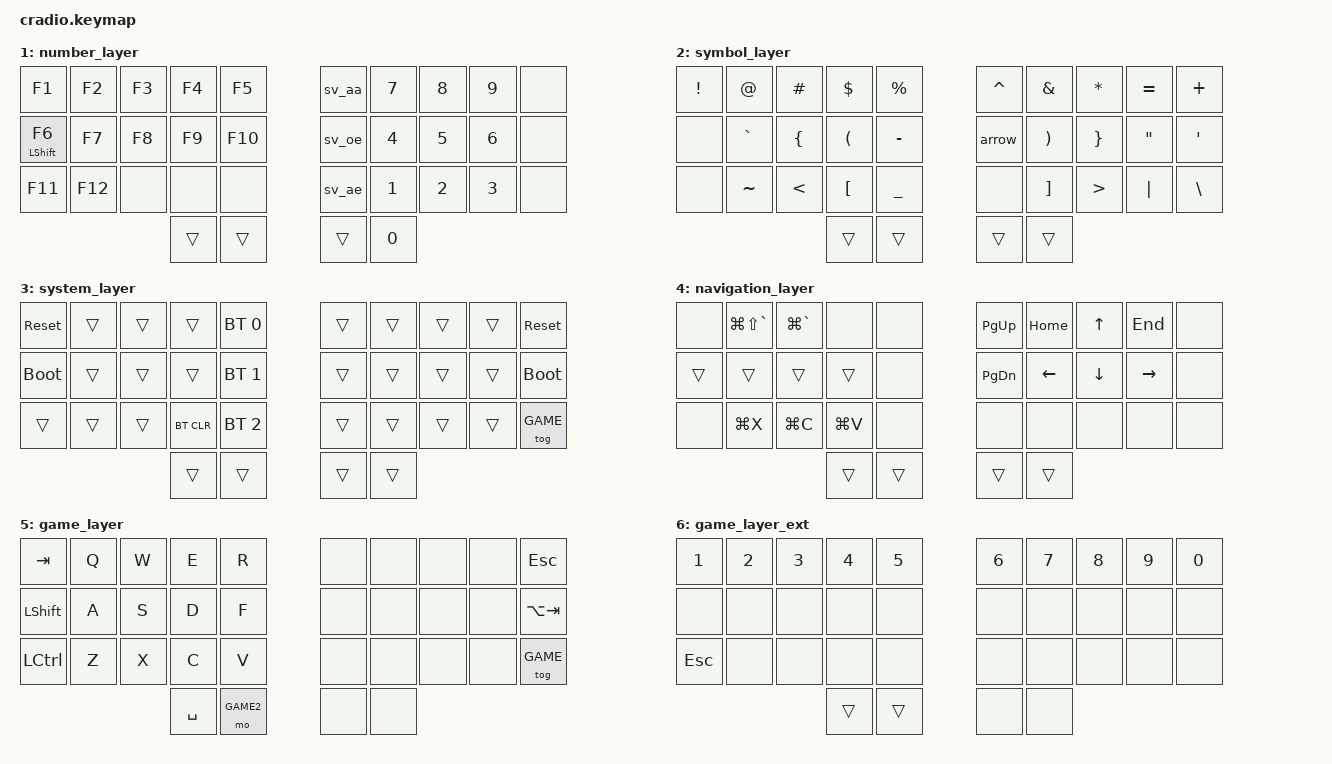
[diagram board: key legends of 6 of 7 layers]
// Copyright (c) 2022 The ZMK Contributors
// SPDX-License-Identifier: MIT

#include <behaviors.dtsi>
#include <dt-bindings/zmk/keys.h>
#include <dt-bindings/zmk/bt.h>

// Layer names
#define DEFAULT 0
#define NUM 1
#define SYM 2
#define SYS 3
#define NAV 4
#define GAME 5
#define GAME2 6

// Home row mods macro
#define HRML(k1,k2,k3,k4) &lhm LSHFT k1  &lhm LCTRL k2  &lhm LALT k3  &lhm LGUI k4
#define HRMR(k1,k2,k3,k4) &rhm RGUI k1  &rhm RALT k2  &rhm RCTRL k3  &rhm RSHFT k4

#define COMBO(NAME, BINDINGS, KEYPOS) \
    combo_##NAME { \
        timeout-ms = <40>; \
        bindings = <BINDINGS>; \
        key-positions = <KEYPOS>; \
	    layers = <DEFAULT NAV>; \
    }

/ {
    behaviors {
        ht: hold_tap {
            label = "hold_tap";
            compatible = "zmk,behavior-hold-tap";
            #binding-cells = <2>;
            flavor = "tap-preferred";
            tapping-term-ms = <250>;
            quick-tap-ms = <150>;
            //global-quick-tap;
            retro-tap;
            bindings = <&kp>, <&kp>;
        };

        lhm: left_homerow_mods {
            compatible = "zmk,behavior-hold-tap";
            label = "LEFT_HOMEROW_MODS";
            #binding-cells = <2>;
            flavor = "balanced";
            tapping-term-ms = <250>;
            //quick-tap-ms = <150>;
            hold-trigger-on-release;
            bindings = <&kp>, <&kp>;
            hold-trigger-key-positions = <5>, <6>, <7>, <8>, <9>, <15>, <16>, <17>, <18>, <19>, <25>, <26>, <27>, <28>, <29>, <32>, <33>;
        };

        rhm: right_homerow_mods {
            compatible = "zmk,behavior-hold-tap";
            label = "RIGHT_HOMEROW_MODS";
            #binding-cells = <2>;
            flavor = "balanced";
            tapping-term-ms = <250>;
            //quick-tap-ms = <150>;
            hold-trigger-on-release;
            bindings = <&kp>, <&kp>;
            hold-trigger-key-positions = <0>, <1>, <2>, <3>, <4>, <10>, <11>, <12>, <13>, <14>, <20>, <21>, <22>, <23>, <24>, <30>, <31>;
        };

        skq: sticky_key_quick_release {
            compatible = "zmk,behavior-sticky-key";
            label = "STICKY_KEY_QUICK_RELEASE";
            #binding-cells = <1>;
            bindings = <&kp>;
            release-after-ms = <2000>;
            quick-release;
        };

        sv_aa: Swedish_aa {
            compatible = "zmk,behavior-mod-morph";
            label = "SWEDISH_AA";
            #binding-cells = <0>;
            bindings = <&kp LA(A)>, <&kp LS(LA(A))>;
            mods = <(MOD_LSFT|MOD_RSFT)>;
        };
        sv_ae: Swedish_ae {
            compatible = "zmk,behavior-mod-morph";
            label = "SWEDISH_AE";
            #binding-cells = <0>;
            bindings = <&sv_ae_L>, <&sv_ae_U>;
            mods = <(MOD_LSFT|MOD_RSFT)>;
        };
        sv_oe: Swedish_oe {
            compatible = "zmk,behavior-mod-morph";
            label = "SWEDISH_OE";
            #binding-cells = <0>;
            bindings = <&sv_oe_L>, <&sv_oe_U>;
            mods = <(MOD_LSFT|MOD_RSFT)>;
        };
    };

    conditional_layers {
        compatible = "zmk,conditional-layers";
        tri_layer {
            if-layers = <NUM SYM>;
            then-layer = <SYS>;
        };
    };

    combos {
/*
 0  1  2  3  4     5  6  7  8  9
10 11 12 13 14    15 16 17 18 19
20 21 22 23 24    25 26 27 28 29
         30 31    32 33
*/
        compatible = "zmk,combos";

        COMBO(esc, &kp ESC, 1 2);
        COMBO(tab, &kp TAB, 11 12);
        COMBO(del, &kp DEL, 6 7);
        COMBO(bksp, &kp BSPC, 7 8);
        COMBO(ent, &kp ENTER, 17 18);
	    COMBO(s_sft, &skq LSHIFT, 26 27);
	    COMBO(capw, &caps_word, 22 23);
    };

    macros {
        sv_ae_L: sv_ae_L {
            label = "MACRO_sv_lower_ae";
            compatible = "zmk,behavior-macro";
            #binding-cells = <0>;
            bindings
                = <&macro_tap &kp LA(U) &kp A>;
        };
        sv_ae_U: sv_ae_U {
            label = "MACRO_sv_upper_AE";
            compatible = "zmk,behavior-macro";
            #binding-cells = <0>;
            bindings
                = <&macro_tap &kp LA(U) &kp LS(A)>;
        };
        sv_oe_L: sv_oe_L {
            label = "MACRO_sv_lower_oe";
            compatible = "zmk,behavior-macro";
            #binding-cells = <0>;
            bindings
                = <&macro_tap &kp LA(U) &kp O>;
        };
        sv_oe_U: sv_oe_U {
            label = "MACRO_sv_upper_OE";
            compatible = "zmk,behavior-macro";
            #binding-cells = <0>;
            bindings
                = <&macro_tap &kp LA(U) &kp LS(O)>;
        };
        arrow: arrow {
            label = "MACRO_cpp_arrow";
            compatible = "zmk,behavior-macro";
            #binding-cells = <0>;
            bindings
                = <&macro_tap &kp MINUS &kp GT>;
        };
    };

    keymap {
        compatible = "zmk,keymap";
        default_layer {
            bindings = <
        //╭──────────┬──────────┬──────────┬──────────┬──────────╮   ╭──────────┬──────────┬──────────┬──────────┬──────────╮
        //│  Q       │  W       │  E       │  R       │  T       │   │  Y       │  U       │  I       │  O       │  P       │
            &kp Q      &kp W      &kp E      &kp R      &kp T          &kp Y      &kp U      &kp I      &kp O      &kp P
        //├──────────┼──────────┼──────────┼──────────┼──────────┤   ├──────────┼──────────┼──────────┼──────────┼──────────┤
        //│  A       │  S       │  D       │  F       │  G       │   │  H       │  J       │  K       │  L       │ ; :      │
            HRML(A,        S,         D,         F)     &kp G          &kp H      HRMR(J,        K,         L,        SEMI)
        //├──────────┼──────────┼──────────┼──────────┼──────────┤   ├──────────┼──────────┼──────────┼──────────┼──────────┤
        //│  Z       │  X       │  C       │  V       │  B       │   │  N       │  M       │ , <      │ . >      │ / ?      │
            &kp Z    &ht LG(X) X  &ht LG(C) C  &ht LG(V) V  &kp B      &kp N      &kp M      &kp COMMA  &kp DOT    &kp FSLH
        //╰──────────┴──────────┴──────────┼──────────┼──────────┤   ├──────────┼──────────┼──────────┴──────────┴──────────╯
                                             &mo NAV    &mo NUM        &mo SYM    &ht LC(LS(LALT)) SPC
        //                                 ╰──────────┴──────────╯   ╰──────────┴──────────╯
            >;
        };

        number_layer {
            bindings = <
        //╭──────────┬──────────┬──────────┬──────────┬──────────╮   ╭──────────┬──────────┬──────────┬──────────┬──────────╮
        //│  F1      │  F2      │  F3      │  F4      │  F5      │   │  å       │  7       │  8       │  9       │          │
            &kp F1     &kp F2     &kp F3     &kp F4     &kp F5         &sv_aa     &kp N7     &kp N8     &kp N9     &none
        //├──────────┼──────────┼──────────┼──────────┼──────────┤   ├──────────┼──────────┼──────────┼──────────┼──────────┤
        //│  F6      │  F7      │  F8      │  F9      │  F10     │   │  ö       │  4       │  5       │  6       │          │
           &ht LSHFT F6  &kp F7   &kp F8     &kp F9     &kp F10        &sv_oe     &kp N4     &kp N5     &kp N6     &none
        //├──────────┼──────────┼──────────┼──────────┼──────────┤   ├──────────┼──────────┼──────────┼──────────┼──────────┤
        //│  F11     │  F12     │          │          │          │   │  ä       │  1       │  2       │  3       │          │
            &kp F11    &kp F12    &none      &none      &none          &sv_ae     &kp N1     &kp N2     &kp N3     &none
        //╰──────────┴──────────┴──────────┼──────────┼──────────┤   ├──────────┼──────────┼──────────┴──────────┴──────────╯
                                             &trans     &trans         &trans     &kp N0
        //                                 ╰──────────┴──────────╯   ╰──────────┴──────────╯
            >;
        };

        symbol_layer {
            bindings = <
        //╭──────────┬──────────┬──────────┬──────────┬──────────╮   ╭──────────┬──────────┬──────────┬──────────┬──────────╮
        //│  !       │  @       │  #       │  $       │  %       │   │  ^       │  &       │  *       │  =       │  +       │
            &kp EXCL   &kp AT     &kp HASH   &kp DLLR   &kp PRCNT      &kp CARET  &kp AMPS   &kp STAR   &kp EQUAL  &kp PLUS
        //├──────────┼──────────┼──────────┼──────────┼──────────┤   ├──────────┼──────────┼──────────┼──────────┼──────────┤
        //│          │  `       │  {       │  (       │  -       │   │  ->      │  )       │  }       │  ''      │  '       │
            &none      &kp GRAVE  &kp LBRC   &kp LPAR   &kp MINUS      &arrow     &kp RPAR   &kp RBRC   &kp DQT    &kp SQT
        //├──────────┼──────────┼──────────┼──────────┼──────────┤   ├──────────┼──────────┼──────────┼──────────┼──────────┤
        //│          │  ~       │  <       │  [       │  _       │   │          │  ]       │  >       │  │       │  \       │
            &none      &kp TILDE  &kp LT     &kp LBKT   &kp UNDER      &none      &kp RBKT   &kp GT     &kp PIPE   &kp BSLH
        //╰──────────┴──────────┴──────────┼──────────┼──────────┤   ├──────────┼──────────┼──────────┴──────────┴──────────╯
                                             &trans     &trans         &trans     &trans
        //                                 ╰──────────┴──────────╯   ╰──────────┴──────────╯
            >;
        };

        system_layer {
            bindings = <
        //╭──────────┬──────────┬──────────┬──────────┬──────────╮   ╭──────────┬──────────┬──────────┬──────────┬──────────╮
        //│ RESET    │          │          │          │PROFILE 0 │   │          │          │          │          │  RESET   │
           &sys_reset   &trans     &trans     &trans    &bt BT_SEL 0    &trans     &trans     &trans     &trans   &sys_reset
        //├──────────┼──────────┼──────────┼──────────┼──────────┤   ├──────────┼──────────┼──────────┼──────────┼──────────┤
        //│BOOTLOADER│          │          │          │PROFILE 1 │   │          │          │          │          │BOOTLOADER│
          &bootloader  &trans     &trans     &trans    &bt BT_SEL 1    &trans     &trans     &trans     &trans    &bootloader
        //├──────────┼──────────┼──────────┼──────────┼──────────┤   ├──────────┼──────────┼──────────┼──────────┼──────────┤
        //│          │          │          │ CLEAR BT │PROFILE 2 │   │          │          │          │          │          │
            &trans     &trans     &trans    &bt BT_CLR &bt BT_SEL 2    &trans     &trans     &trans     &trans     &tog GAME
        //╰──────────┴──────────┴──────────┼──────────┼──────────┤   ├──────────┼──────────┼──────────┴──────────┴──────────╯
                                             &trans     &trans         &trans     &trans
        //                                 ╰──────────┴──────────╯   ╰──────────┴──────────╯
            >;
        };

        navigation_layer {
            bindings = <
        //╭──────────┬──────────┬──────────┬──────────┬──────────╮   ╭──────────┬──────────┬──────────┬──────────┬──────────╮
        //│          │ PREV WIN │ NEXT WIN │          │          │   │ PAGE UP  │ HOME     │ UP       │ END      │          │
            &none    &kp LG(LS(GRAVE)) &kp LG(GRAVE) &none &none       &kp PG_UP  &kp HOME   &kp UP     &kp END    &none
        //├──────────┼──────────┼──────────┼──────────┼──────────┤   ├──────────┼──────────┼──────────┼──────────┼──────────┤
        //│          │          │          │          │          │   │ PAGE DN  │ LEFT     │ DOWN     │ RIGHT    │          │
            &trans     &trans     &trans     &trans     &none         &kp PG_DN  &kp LEFT   &kp DOWN   &kp RIGHT  &none
        //├──────────┼──────────┼──────────┼──────────┼──────────┤   ├──────────┼──────────┼──────────┼──────────┼──────────┤
        //│          │  CUT     │  COPY    │  PASTE   │          │   │          │          │          │          │          │
            &none      &kp LG(X)  &kp LG(C)  &kp LG(V)  &none          &none      &none      &none      &none      &none
        //╰──────────┴──────────┴──────────┼──────────┼──────────┤   ├──────────┼──────────┼──────────┴──────────┴──────────╯
                                             &trans     &trans         &trans     &trans
        //                                 ╰──────────┴──────────╯   ╰──────────┴──────────╯
            >;
        };

        game_layer {
            bindings = <
        //╭──────────┬──────────┬──────────┬──────────┬──────────╮   ╭──────────┬──────────┬──────────┬──────────┬──────────╮
        //│  TAB     │  Q       │  W       │  E       │  R       │   │  ?       │  ?       │  ?       │  ?       │  ESC     │
            &kp TAB    &kp Q      &kp W      &kp E      &kp R          &none      &none      &none      &none      &kp ESC
        //├──────────┼──────────┼──────────┼──────────┼──────────┤   ├──────────┼──────────┼──────────┼──────────┼──────────┤
        //│  SHFT    │  A       │  S       │  D       │  F       │   │  ?       │  ?       │  ?       │  ?       │ ALT-TAB  │
           &kp LSHIFT  &kp A      &kp S      &kp D      &kp F          &none      &none      &none      &none     &kp LA(TAB)
        //├──────────┼──────────┼──────────┼──────────┼──────────┤   ├──────────┼──────────┼──────────┼──────────┼──────────┤
        //│  CTRL    │  Z       │  X       │  C       │  V       │   │  ?       │  ?       │  ?       │  ?       │ un-game
           &kp LCTRL   &kp Z      &kp X      &kp C      &kp V          &none      &none      &none      &none      &tog GAME
        //╰──────────┴──────────┴──────────┼──────────┼──────────┤   ├──────────┼──────────┼──────────┴──────────┴──────────╯
                                             &kp SPC    &mo GAME2      &none     &none
        //                                 ╰──────────┴──────────╯   ╰──────────┴──────────╯
            >;
        };

        game_layer_ext {
            bindings = <
        //╭──────────┬──────────┬──────────┬──────────┬──────────╮   ╭──────────┬──────────┬──────────┬──────────┬──────────╮
        //│  1       │  2       │  3       │  4       │  5       │   │  6       │  7       │  8       │  9       │  0       │
            &kp N1     &kp N2     &kp N3     &kp N4     &kp N5         &kp N6     &kp N7     &kp N8     &kp N9     &kp N0
        //├──────────┼──────────┼──────────┼──────────┼──────────┤   ├──────────┼──────────┼──────────┼──────────┼──────────┤
        //│  ?       │  ?       │  ?       │  ?       │  ?       │   │  ?       │  ?       │  ?       │  ?       │  ?       │
            &none      &none      &none      &none      &none          &none      &none      &none      &none      &none
        //├──────────┼──────────┼──────────┼──────────┼──────────┤   ├──────────┼──────────┼──────────┼──────────┼──────────┤
        //│  ESC     │  ?       │  ?       │  ?       │  ?       │   │  ?       │  ?       │  ?       │  ?       │  ?
            &kp ESC    &none      &none      &none      &none          &none      &none      &none      &none      &none
        //╰──────────┴──────────┴──────────┼──────────┼──────────┤   ├──────────┼──────────┼──────────┴──────────┴──────────╯
                                             &trans     &trans         &none      &none
        //                                 ╰──────────┴──────────╯   ╰──────────┴──────────╯
            >;
        };

    };
};
